AUTOSAR XML (schema 4-0-3)
package /AppMode/ApplicationSwComponentTypes
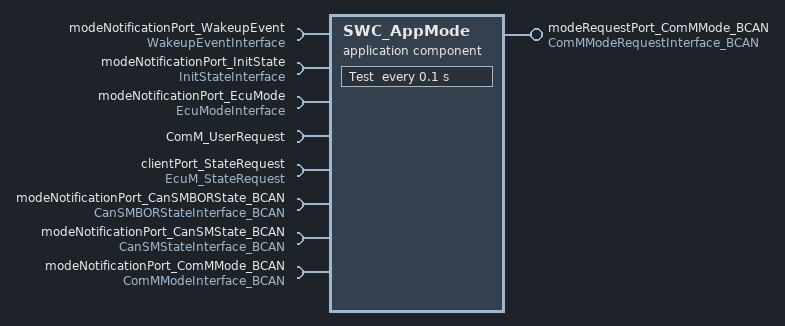
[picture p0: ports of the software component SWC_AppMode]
  application sw component type SWC_AppMode
    8 x require port:
      modeNotificationPort_WakeupEvent: mode-switch-receiver-com-spec{enhanced-mode-api=true, mode-group=WakeupEvent, supports-asynchronous-mode-switch=true}, required-interface=WakeupEventInterface
      modeNotificationPort_InitState: mode-switch-receiver-com-spec{enhanced-mode-api=true, mode-group=InitState, supports-asynchronous-mode-switch=true}, required-interface=InitStateInterface
      modeNotificationPort_EcuMode: mode-switch-receiver-com-spec{enhanced-mode-api=true, mode-group=EcuMode, supports-asynchronous-mode-switch=true}, required-interface=EcuModeInterface
      ComM_UserRequest: client-com-spec=GetCurrentComMode, required-interface=ComM_UserRequest
      clientPort_StateRequest: required-com-specs=[ReleaseRUN, RequestRUN, RequestSleep, RequestReset, RequestOff, SetRunState], required-interface=EcuM_StateRequest
      modeNotificationPort_CanSMBORState_BCAN: mode-switch-receiver-com-spec{enhanced-mode-api=true, mode-group=CanSMBORState_BCAN, supports-asynchronous-mode-switch=true}, required-interface=CanSMBORStateInterface_BCAN
      modeNotificationPort_CanSMState_BCAN: mode-switch-receiver-com-spec{enhanced-mode-api=true, mode-group=CanSMState_BCAN, supports-asynchronous-mode-switch=true}, required-interface=CanSMStateInterface_BCAN
      modeNotificationPort_ComMMode_BCAN: mode-switch-receiver-com-spec{enhanced-mode-api=true, mode-group=ComMMode_BCAN, supports-asynchronous-mode-switch=true}, required-interface=ComMModeInterface_BCAN
    provide port modeRequestPort_ComMMode_BCAN: nonqueued-sender-com-spec=ComMMode_BCAN, provided-interface=ComMModeRequestInterface_BCAN
    behavior SwcIB_AppMode: data-type-mapping=[MAP_CanSMBORState, MAP_ComMMode, EcuModeMap, MAP_InitState, MAP_PduGroup, MAP_WakeupEvent]
      timing event TE_AppMode_Test: start-on-event=Test, period=0.1
      12 x swc mode switch event, all with activation=ON-ENTRY:
        SMSE_Entry_BusOffStateSwitched_modeNotificationPort_CanSMBORState_BCAN_CanSMBORState_BCAN_COMPLETE: start-on-event=CanSMBORStateSwitched_BCAN, mode=modeNotificationPort_CanSMBORState_BCAN.CanSMBORState_BCAN.COMPLETE
        SMSE_Entry_BusOffStateSwitched_modeNotificationPort_CanSMBORState_BCAN_CanSMBORState_BCAN_START: start-on-event=CanSMBORStateSwitched_BCAN, mode=modeNotificationPort_CanSMBORState_BCAN.CanSMBORState_BCAN.START
        SMSE_Entry_ComMModeSwitched_BCAN_modeNotificationPort_ComMMode_BCAN_ComMMode_BCAN_NO_COM: start-on-event=ComMModeSwitched_BCAN, mode=modeNotificationPort_ComMMode_BCAN.ComMMode_BCAN.NO_COM
        SMSE_Entry_ComMModeSwitched_BCAN_modeNotificationPort_ComMMode_BCAN_ComMMode_BCAN_SILENT_COM: start-on-event=ComMModeSwitched_BCAN, mode=modeNotificationPort_ComMMode_BCAN.ComMMode_BCAN.SILENT_COM
        SMSE_Entry_ComMModeSwitched_BCAN_modeNotificationPort_ComMMode_BCAN_ComMMode_BCAN_FULL_COM: start-on-event=ComMModeSwitched_BCAN, mode=modeNotificationPort_ComMMode_BCAN.ComMMode_BCAN.FULL_COM
        SMSE_Entry_EcuModeSwitched_modeNotificationPort_EcuMode_EcuMode_ECUM_STATE_RUN: start-on-event=EcuModeSwitched, mode=modeNotificationPort_EcuMode.EcuMode.ECUM_STATE_RUN
        SMSE_Entry_EcuModeSwitched_modeNotificationPort_EcuMode_EcuMode_ECUM_STATE_SHUTDOWN: start-on-event=EcuModeSwitched, mode=modeNotificationPort_EcuMode.EcuMode.ECUM_STATE_SHUTDOWN
        SMSE_Entry_EcuModeSwitched_modeNotificationPort_EcuMode_EcuMode_ECUM_STATE_PREP_SHUTDOWN: start-on-event=EcuModeSwitched, mode=modeNotificationPort_EcuMode.EcuMode.ECUM_STATE_PREP_SHUTDOWN
        SMSE_Entry_EcuModeSwitched_modeNotificationPort_EcuMode_EcuMode_ECUM_STATE_SLEEP: start-on-event=EcuModeSwitched, mode=modeNotificationPort_EcuMode.EcuMode.ECUM_STATE_SLEEP
        SMSE_Entry_EcuModeSwitched_modeNotificationPort_EcuMode_EcuMode_ECUM_STATE_OFF: start-on-event=EcuModeSwitched, mode=modeNotificationPort_EcuMode.EcuMode.ECUM_STATE_OFF
        SMSE_Entry_EcuModeSwitched_modeNotificationPort_EcuMode_EcuMode_ECUM_STATE_RESET: start-on-event=EcuModeSwitched, mode=modeNotificationPort_EcuMode.EcuMode.ECUM_STATE_RESET
        SMSE_Entry_InitCompleted_modeNotificationPort_InitState_InitState_COMPLETE: start-on-event=InitCompleted, mode=modeNotificationPort_InitState.InitState.COMPLETE
      6 x runnable:
        Test: symbol=AppMode_Test
          data-send-points:
            access DSP_Test_modeRequestPort_ComMMode_BCAN_ComMMode_BCAN: accessed-variable=modeRequestPort_ComMMode_BCAN.ComMMode_BCAN, scope=COMMUNICATION-INTER-ECU
          6 x sync call:
            SSCP_Test_ComM_UserRequest_GetCurrentComMode: operation=ComM_UserRequest.GetCurrentComMode
            SSCP_Test_clientPort_StateRequest_ReleaseRUN: operation=clientPort_StateRequest.ReleaseRUN
            SSCP_Test_clientPort_StateRequest_RequestRUN: operation=clientPort_StateRequest.RequestRUN, timeout=0.0
            SSCP_Test_clientPort_StateRequest_RequestSleep: operation=clientPort_StateRequest.RequestSleep
            SSCP_Test_clientPort_StateRequest_RequestReset: operation=clientPort_StateRequest.RequestReset
            SSCP_Test_clientPort_StateRequest_RequestOff: operation=clientPort_StateRequest.RequestOff
        EcuModeSwitched: can-be-invoked-concurrently=true, symbol=AppMode_EcuModeSwitched
          data-send-points:
            access DSP_EcuModeSwitched_modeRequestPort_ComMMode_BCAN_ComMMode_BCAN: accessed-variable=modeRequestPort_ComMMode_BCAN.ComMMode_BCAN, scope=COMMUNICATION-INTER-ECU
          mode-access-point mode-group=modeNotificationPort_EcuMode.EcuMode:
            ident MRAP_EcuModeSwitched_modeNotificationPort_EcuMode_EcuMode
          sync call SSCP_EcuModeSwitched_clientPort_StateRequest_RequestRUN: operation=clientPort_StateRequest.RequestRUN
          sync call SSCP_EcuModeSwitched_clientPort_StateRequest_SetRunState: operation=clientPort_StateRequest.SetRunState
        WakeupEventValidated: can-be-invoked-concurrently=true, symbol=AppMode_WakeupEventValidated
          data-send-points:
            access DSP_WakeupEventValidated_modeRequestPort_ComMMode_BCAN_ComMMode_BCAN: accessed-variable=modeRequestPort_ComMMode_BCAN.ComMMode_BCAN, scope=COMMUNICATION-INTER-ECU
          mode-access-point mode-group=modeNotificationPort_WakeupEvent.WakeupEvent:
            ident MRAP_WakeupEventValidated_modeNotificationPort_WakeupEvent_WakeupEvent
          sync call SSCP_WakeupEventValidated_clientPort_StateRequest_RequestRUN: operation=clientPort_StateRequest.RequestRUN, timeout=0.0
        CanSMBORStateSwitched_BCAN: can-be-invoked-concurrently=true, symbol=AppMode_CanSMBORStateSwitched_BCAN
          mode-access-point mode-group=modeNotificationPort_CanSMBORState_BCAN.CanSMBORState_BCAN:
            ident MRAP_BusStateSwitched_modeNotificationPort_CanSMBORState_BCAN_CanSMBORState_BCAN
        ComMModeSwitched_BCAN: can-be-invoked-concurrently=true, symbol=AppMode_ComMModeSwitched_BCAN
          mode-access-point mode-group=modeNotificationPort_ComMMode_BCAN.ComMMode_BCAN:
            ident MRAP_ComMModeSwitched_BCAN_modeNotificationPort_ComMMode_BCAN_ComMMode_BCAN
        InitCompleted: can-be-invoked-concurrently=true, symbol=AppMode_InitCompleted
          mode-access-point mode-group=modeNotificationPort_InitState.InitState:
            ident MRAP_InitCompleted_modeNotificationPort_InitState_InitState
      swc service dependency SwcServiceDependency_BswM
        assigned-ports:
          port-prototype=modeNotificationPort_WakeupEvent, role=Custom
          port-prototype=modeNotificationPort_InitState, role=Custom
          port-prototype=modeNotificationPort_EcuMode, role=Custom
          port-prototype=modeNotificationPort_CanSMBORState_BCAN, role=Custom
          port-prototype=modeNotificationPort_CanSMState_BCAN, role=Custom
          port-prototype=modeNotificationPort_ComMMode_BCAN, role=Custom
          port-prototype=modeRequestPort_ComMMode_BCAN, role=Custom
        service-needs:
          bsw mgr needs BswMgrNeeds
